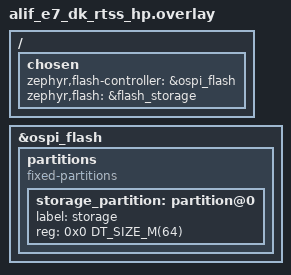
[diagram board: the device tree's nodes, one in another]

/delete-node/ &storage_partition;

/ {
	chosen {
		zephyr,flash-controller = &ospi_flash;
		zephyr,flash = &flash_storage;
	};
};

&ospi_flash {
	partitions {
		#address-cells = <1>;
		#size-cells = <1>;
		compatible = "fixed-partitions";

		/* Set 64MB of storage flash */
		storage_partition: partition@0 {
			label = "storage";
			reg = <0x0 DT_SIZE_M(64)>;
		};
	};
};
